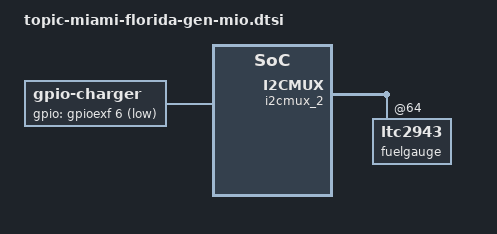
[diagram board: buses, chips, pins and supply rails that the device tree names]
/ {
		charger: battery-charger {
			compatible = "gpio-charger";
			charger-type = "mains";
			gpios = <&gpioexf 6 1>; /* Pin 6 of IO expander, active low */
		};
};

&i2cmux_2 {
	/* Battery gauge */
	fuelgauge: battery-gauge {
		compatible = "ltc2943";
		reg = <0x64>;
		lltc,resistor-sense = <15>; /* 15 mOhm */
		lltc,prescaler-exponent = <5>; /* 2^(2*5) = 1024 */
		power-supplies = <&charger>;
	};
};
